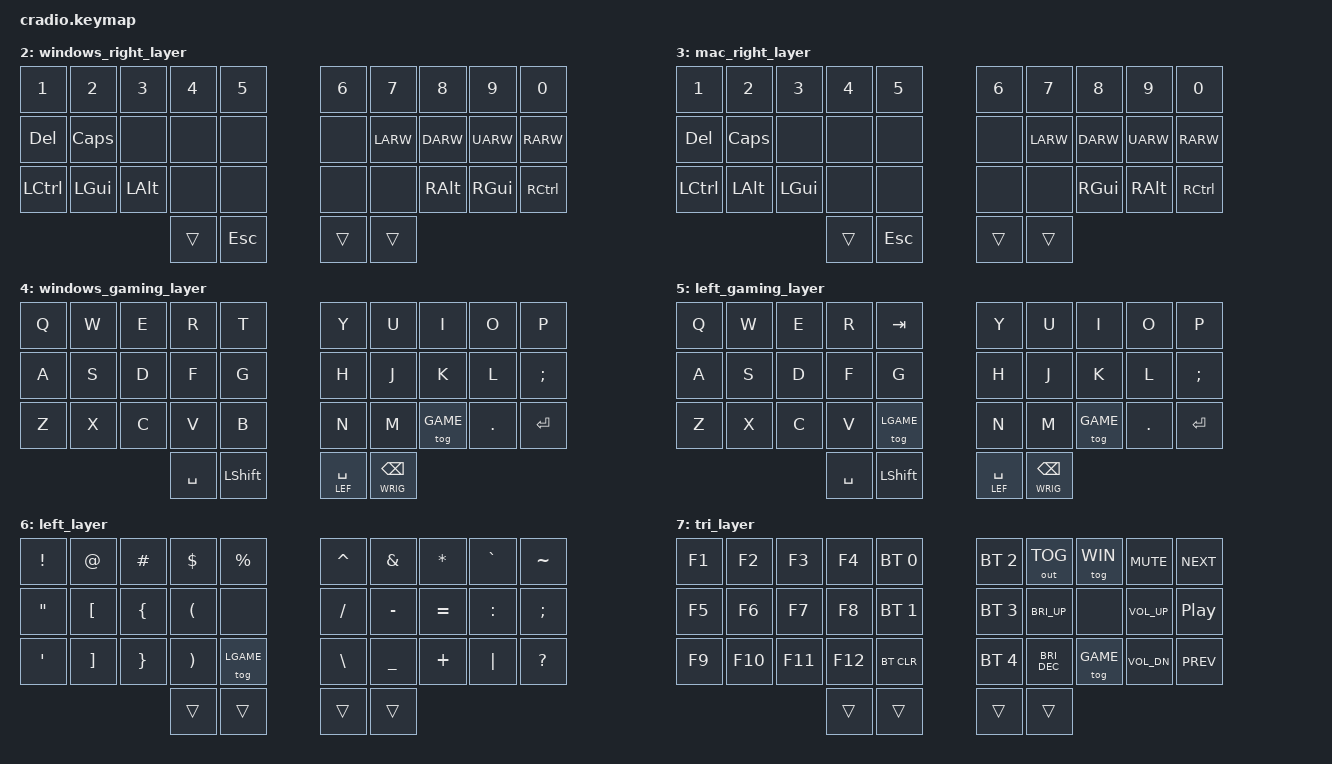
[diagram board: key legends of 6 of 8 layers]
// Copyright (c) 2022 The ZMK Contributors
// SPDX-License-Identifier: MIT

#include <behaviors.dtsi>
#include <dt-bindings/zmk/keys.h>
#include <dt-bindings/zmk/bt.h>
#include <dt-bindings/zmk/outputs.h>

// Home row mods macro
#define HRML(k2,k3,k4) &ht LALT k2  &ht LCTRL k3  &ht LGUI k4
#define HRMR(k1,k2,k3) &ht RGUI k1  &ht RCTRL k2  &ht RALT k3
#define WHRML(k2,k3,k4) &ht LALT k2  &ht LGUI k3  &ht LCTRL k4
#define WHRMR(k1,k2,k3) &ht RCTRL k1  &ht RGUI k2  &ht RALT k3

#define MAC 0
#define WIN 1
#define WRIG 2
#define MRIG 3
#define GAME 4
#define LGAME 5
#define LEF 6
#define TRI 7

/ {
    behaviors {
        ht: hold_tap {
            label = "hold_tap";
            compatible = "zmk,behavior-hold-tap";
            #binding-cells = <2>;
            flavor = "tap-preferred";
            tapping-term-ms = <220>;
            quick-tap-ms = <150>;
            global-quick-tap;
            bindings = <&kp>, <&kp>;
        };
    };

    conditional_layers {
        compatible = "zmk,conditional-layers";
        tri_layer_win {
            if-layers = <WRIG LEF>;
            then-layer = <TRI>;
        };
        tri_layer_mac {
            if-layers = <MRIG LEF>;
            then-layer = <TRI>;
        };
    };

    keymap {
        compatible = "zmk,keymap";
        default_layer {
            bindings = <
        //╭──────────┬──────────┬──────────┬──────────┬──────────╮   ╭──────────┬──────────┬──────────┬──────────┬──────────╮
        //│  Q       │  W       │  E       │  R       │  T       │   │  Y       │  U       │  I       │  O       │  P       │
            &kp Q      &kp W      &kp E      &kp R      &kp T          &kp Y      &kp U      &kp I      &kp O      &kp P
        //├──────────┼──────────┼──────────┼──────────┼──────────┤   ├──────────┼──────────┼──────────┼──────────┼──────────┤
        //│  A       │  S       │  D       │  F       │  G       │   │  H       │  J       │  K       │  L       │  ; :     │
            &kp A     HRML(S,         D,         F)     &kp G          &kp H      HRMR(J,        K,           L)   &kp SEMI
        //├──────────┼──────────┼──────────┼──────────┼──────────┤   ├──────────┼──────────┼──────────┼──────────┼──────────┤
        //│  Z       │  X       │  C       │  V       │  B       │   │  N       │  M       │ , <      │ . >      │ ENTER    │
            &kp Z      &kp X      &kp C      &kp V      &kp B          &kp N      &kp M      &kp COMMA  &kp DOT    &kp ENTER
        //╰──────────┴──────────┴──────────┼──────────┼──────────┤   ├──────────┼──────────┼──────────┴──────────┴──────────╯
                                           &lt LEF TAB  &kp LSHIFT    &kp SPACE  &lt MRIG BSPC
        //                                 ╰──────────┴──────────╯   ╰──────────┴──────────╯
            >;
        };

        windows_layer {
            bindings = <
        //╭──────────┬──────────┬──────────┬──────────┬──────────╮   ╭──────────┬──────────┬──────────┬──────────┬──────────╮
        //│  Q       │  W       │  E       │  R       │  T       │   │  Y       │  U       │  I       │  O       │  P       │
            &kp Q      &kp W      &kp E      &kp R      &kp T          &kp Y      &kp U      &kp I      &kp O      &kp P
        //├──────────┼──────────┼──────────┼──────────┼──────────┤   ├──────────┼──────────┼──────────┼──────────┼──────────┤
        //│  A       │  S       │  D       │  F       │  G       │   │  H       │  J       │  K       │  L       │  ; :     │
            &kp A    WHRML(S,         D,         F)     &kp G          &kp H      WHRMR(J,        K,         L)    &kp SEMI
        //├──────────┼──────────┼──────────┼──────────┼──────────┤   ├──────────┼──────────┼──────────┼──────────┼──────────┤
        //│  Z       │  X       │  C       │  V       │  B       │   │  N       │  M       │ , <      │ . >      │ ENTER    │
            &kp Z      &kp X      &kp C      &kp V      &kp B          &kp N      &kp M      &kp COMMA  &kp DOT    &kp ENTER
        //╰──────────┴──────────┴──────────┼──────────┼──────────┤   ├──────────┼──────────┼──────────┴──────────┴──────────╯
                                           &lt LEF TAB  &kp LSHIFT    &kp SPACE  &lt WRIG BSPC
        //                                 ╰──────────┴──────────╯   ╰──────────┴──────────╯
            >;
        };

        windows_right_layer {
            bindings = <
        //╭──────────┬──────────┬──────────┬──────────┬──────────╮   ╭──────────┬──────────┬──────────┬──────────┬──────────╮
        //│ 1        │  2       │  3       │  4       │  5       │   │ 6        │ 7        │ 8        │ 9        │   0      │
            &kp N1    &kp N2     &kp N3     &kp N4     &kp N5          &kp N6     &kp N7     &kp N8     &kp N9      &kp N0
        //├──────────┼──────────┼──────────┼──────────┼──────────┤   ├──────────┼──────────┼──────────┼──────────┼──────────┤
        //│ DELETE   │ CapsLock │          │          │          |   |          │ LEFT     │ DOWN     │ UP       │ RIGHT    │
            &kp DEL   &kp CAPS    &none     &none     &none          &none    &kp LARW   &kp DARW   &kp UARW   &kp RARW 
        //├──────────┼──────────┼──────────┼──────────┼──────────┤   ├──────────┼──────────┼──────────┼──────────┼──────────┤
        //│          │          │          │          │          │   │          │          │          │          │          │
            &kp LCTRL  &kp LGUI   &kp LALT   &none      &none        &none     &none     &kp RALT   &kp RGUI   &kp RCTRL
        //╰──────────┴──────────┴──────────┼──────────┼──────────┤   ├──────────┼──────────┼──────────┴──────────┴──────────╯
                                             &trans     &kp ESC        &trans     &trans
        //                                 ╰──────────┴──────────╯   ╰──────────┴──────────╯
            >;
        };

        mac_right_layer {
            bindings = <
        //╭──────────┬──────────┬──────────┬──────────┬──────────╮   ╭──────────┬──────────┬──────────┬──────────┬──────────╮
        //│ 1        │  2       │  3       │  4       │  5       │   │ 6        │ 7        │ 8        │ 9        │   0      │
            &kp N1    &kp N2     &kp N3     &kp N4     &kp N5          &kp N6     &kp N7     &kp N8     &kp N9      &kp N0
        //├──────────┼──────────┼──────────┼──────────┼──────────┤   ├──────────┼──────────┼──────────┼──────────┼──────────┤
        //│ DELETE   │ CapsLock │          │          │          |   |          │ LEFT     │ DOWN     │ UP       │ RIGHT    │
            &kp DEL   &kp CAPS    &none     &none     &none          &none    &kp LARW   &kp DARW   &kp UARW   &kp RARW 
        //├──────────┼──────────┼──────────┼──────────┼──────────┤   ├──────────┼──────────┼──────────┼──────────┼──────────┤
        //│          │          │          │          │          │   │          │          │          │          │          │
            &kp LCTRL  &kp LALT  &kp LGUI   &none      &none            &none     &none     &kp RGUI   &kp RALT  &kp RCTRL 
        //╰──────────┴──────────┴──────────┼──────────┼──────────┤   ├──────────┼──────────┼──────────┴──────────┴──────────╯
                                             &trans     &kp ESC        &trans     &trans
        //                                 ╰──────────┴──────────╯   ╰──────────┴──────────╯
            >;
        };

        windows_gaming_layer {
            bindings = <
        //╭──────────┬──────────┬──────────┬──────────┬──────────╮   ╭──────────┬──────────┬──────────┬──────────┬──────────╮
        //│  Q       │  W       │  E       │  R       │  T       │   │  Y       │  U       │  I       │  O       │  P       │
            &kp Q      &kp W      &kp E      &kp R      &kp T          &kp Y      &kp U      &kp I      &kp O      &kp P
        //├──────────┼──────────┼──────────┼──────────┼──────────┤   ├──────────┼──────────┼──────────┼──────────┼──────────┤
        //│  A       │  S       │  D       │  F       │  G       │   │  H       │  J       │  K       │  L       │  ; :     │
            &kp A      &kp S      &kp D       &kp F     &kp G          &kp H      &kp J       &kp K      &kp L    &kp SEMI
        //├──────────┼──────────┼──────────┼──────────┼──────────┤   ├──────────┼──────────┼──────────┼──────────┼──────────┤
        //│  Z       │  X       │  C       │  V       │  B       │   │  N       │  M       │ GAMING   │ . >      │ ENTER    │
            &kp Z      &kp X      &kp C      &kp V      &kp B          &kp N      &kp M      &tog GAME  &kp DOT    &kp ENTER
        //╰──────────┴──────────┴──────────┼──────────┼──────────┤   ├──────────┼──────────┼──────────┴──────────┴──────────╯
                                           &kp SPACE  &kp LSHIFT      &lt LEF SPACE  &lt WRIG BSPC
        //                                 ╰──────────┴──────────╯   ╰──────────┴──────────╯
            >;
        };

        left_gaming_layer {
            bindings = <
        //╭──────────┬──────────┬──────────┬──────────┬──────────╮   ╭──────────┬──────────┬──────────┬──────────┬──────────╮
        //│  Q       │  W       │  E       │  R       │  TAB       │   │  Y       │  U       │  I       │  O       │  P       │
            &kp Q      &kp W      &kp E      &kp R      &kp TAB          &kp Y      &kp U      &kp I      &kp O      &kp P
        //├──────────┼──────────┼──────────┼──────────┼──────────┤   ├──────────┼──────────┼──────────┼──────────┼──────────┤
        //│  A       │  S       │  D       │  F       │  G       │   │  H       │  J       │  K       │  L       │  ; :     │
            &kp A      &kp S      &kp D       &kp F     &kp G          &kp H      &kp J       &kp K      &kp L    &kp SEMI
        //├──────────┼──────────┼──────────┼──────────┼──────────┤   ├──────────┼──────────┼──────────┼──────────┼──────────┤
        //│  Z       │  X       │  C       │  V       │ LGAME    │   │  N       │  M       │ GAMING   │ . >      │ ENTER    │
            &kp Z      &kp X      &kp C      &kp V      &tog LGAME          &kp N      &kp M      &tog GAME  &kp DOT    &kp ENTER
        //╰──────────┴──────────┴──────────┼──────────┼──────────┤   ├──────────┼──────────┼──────────┴──────────┴──────────╯
                                           &kp SPACE  &kp LSHIFT      &lt LEF SPACE  &lt WRIG BSPC
        //                                 ╰──────────┴──────────╯   ╰──────────┴──────────╯
            >;
        };

        left_layer {
            bindings = <
        //╭──────────┬──────────┬──────────┬──────────┬──────────╮   ╭──────────┬──────────┬──────────┬──────────┬──────────╮
        //│  !       │  @       │  #       │  $       │  %       │   │  ^       │  &       │  *       │  `       │  ~       │
            &kp EXCL   &kp AT     &kp HASH   &kp DLLR   &kp PRCNT      &kp CARET  &kp AMPS   &kp ASTRK  &kp GRAVE   &kp TILDE
        //├──────────┼──────────┼──────────┼──────────┼──────────┤   ├──────────┼──────────┼──────────┼──────────┼──────────┤
        //│  "       │  [       │          │          │          │   │   /      │  -       │  =       │     :    │  ;       │
            &kp DQT    &kp LBKT   &kp LBRC   &kp LPAR   &none         &kp FSLH   &kp MINUS  &kp EQUAL  &kp COLON   &kp SEMI
        //├──────────┼──────────┼──────────┼──────────┼──────────┤   ├──────────┼──────────┼──────────┼──────────┼──────────┤
        //│  '       │  ]       │          │          │  LGAME   │   │    \     │  _       │  +       │  │       │   ?      │
            &kp SQT     &kp RBKT   &kp RBRC   &kp RPAR   &tog LGAME        &kp BSLH   &kp UNDER  &kp PLUS   &kp PIPE  &kp QMARK
        //╰──────────┴──────────┴──────────┼──────────┼──────────┤   ├──────────┼──────────┼──────────┴──────────┴──────────╯
                                             &trans     &trans         &trans     &trans
        //                                 ╰──────────┴──────────╯   ╰──────────┴──────────╯
            >;
        };

        tri_layer {
            bindings = <
        //╭──────────┬──────────┬──────────┬───────────┬────────────╮   ╭────────────┬────────────┬──────────┬───────────┬──────────╮
        //│  F1      │  F2      │  F3      │  F4       │ PROFILE 0  │   │ PROFILE 2  │ TOGGLEOUT  │ WINDOWS  │ VOL MUTE  │ NEXTSONG │
            &kp F1     &kp F2     &kp F3     &kp F4     &bt BT_SEL 0     &bt BT_SEL 2  &out OUT_TOG &tog WIN  &kp C_MUTE  &kp C_NEXT
        //├──────────┼──────────┼──────────┼───────────┼────────────┤   ├────────────┼────────────┼──────────┼───────────┼──────────┤
        //│  F5      │  F6      │  F7      │  F8       │ PROFILE 1  │   │ PROFILE 3  │ INC BRIGHT │          │  VOL UP   │PAUSEMUSIC│
            &kp F5     &kp F6     &kp F7     &kp F8     &bt BT_SEL 1     &bt BT_SEL 3  &kp C_BRI_UP  &none   &kp C_VOL_UP  &kp C_PP
        //├──────────┼──────────┼──────────┼───────────┼────────────┤   ├────────────┼────────────┼──────────┼───────────┼──────────┤
        //│  F9      │  F10     │  F11     │  F12      │  CLEAR BT  │   │ PROFILE 4  │ DEC BRIGHT │ GAMING   |  VOL DOWN │ PREVSONG │
            &kp F9     &kp F10    &kp F11    &kp F12     &bt BT_CLR      &bt BT_SEL 4  &kp C_BRI_DEC &tog GAME &kp C_VOL_DN &kp C_PREV
        //╰──────────┴──────────┴──────────┼───────────┼────────────┤   ├────────────┼────────────┼──────────┴───────────┴──────────╯
                                                &trans     &trans         &trans     &trans
        //                                  ╰───────────┴──────────╯   ╰──────────┴────────────╯
            >;
        };
    };
};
